# MCF5441x register map
Vendor: NXP; File version: 1.0
Registers are 32-bit, read-write, reset 0x0 unless marked. A register's access mark holds for its fields unless they carry their own. Offsets are from the block's base; [hi:lo] are bit positions; 'fields as' and 'values as' point back to an identical list.

## PIT0
Base 0xFC080000
Same registers: PIT1 0xFC084000, PIT2 0xFC088000, PIT3 0xFC08C000
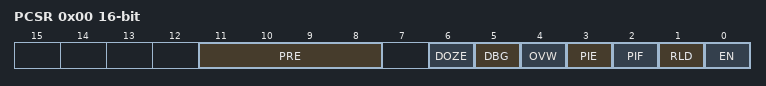
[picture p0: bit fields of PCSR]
0x00 PCSR 16-bit
  [11:8] PRE
  [6] DOZE
  [5] DBG
  [4] OVW
  [3] PIE
    0=DISABLED; 1=ENABLED
  [2] PIF write-1-clears
  [1] RLD
  [0] EN
    0=DISABLED; 1=ENABLED
0x02 PMR 16-bit reset 0xFFFF
  [15:0] PM
0x04 PCNTR 16-bit ro reset 0xFFFF

## SCM
Base 0xFC040000
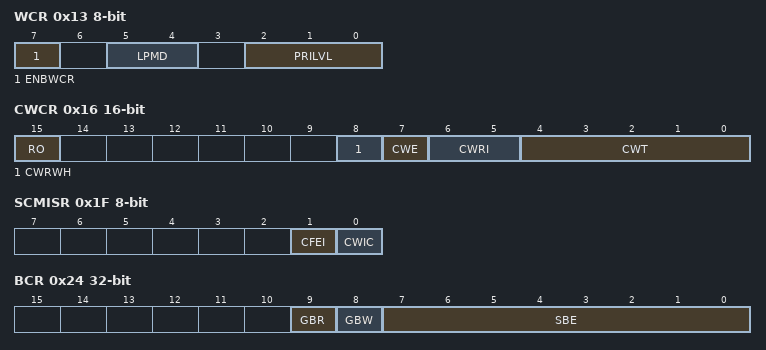
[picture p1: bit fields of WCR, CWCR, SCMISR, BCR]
0x13 WCR 8-bit
  [7] ENBWCR
  [5:4] LPMD
    0=RUN; 1=DOZE; 2=WAIT; 3=STOP
  [2:0] PRILVL
0x16 CWCR 16-bit
  [15] RO
  [8] CWRWH
  [7] CWE
    0=DISABLED; 1=ENABLED
  [6:5] CWRI
  [4:0] CWT
0x1B CWSR 8-bit reset not defined
0x1F SCMISR 8-bit
  [1] CFEI write-1-clears, [0] CWIC write-1-clears
0x24 BCR
  [9] GBR
    0=DISABLED; 1=ENABLED
  [8] GBW
    0=DISABLED; 1=ENABLED
  [7:0] SBE
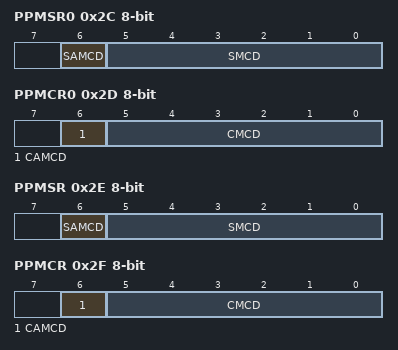
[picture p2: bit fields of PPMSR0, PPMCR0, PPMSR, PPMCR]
0x2C PPMSR0 8-bit wo
  [6] SAMCD, [5:0] SMCD
0x2D PPMCR0 8-bit wo
  [6] CAMCD, [5:0] CMCD
0x2E PPMSR 8-bit wo
  [6] SAMCD, [5:0] SMCD
0x2F PPMCR 8-bit wo
  [6] CAMCD, [5:0] CMCD
0x30 PPMHR0 reset 0x7E1EFBFF
0x34 PPMLR0 reset 0xFFDEF300
0x38 PPMHR reset 0xFFFFFFCF
0x3C PPMLR reset 0x3F00C0F4
0x70 CFADR ro reset not defined
  [31:0] ADDR
0x75 CFIER 8-bit
  [0] ECFEI
0x76 CFLOC 8-bit ro reset not defined
  [7] LOC
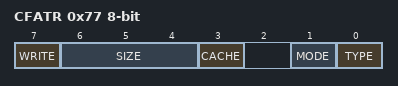
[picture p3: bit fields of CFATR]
0x77 CFATR 8-bit ro reset not defined
  [7] WRITE
    0=READ_ACCESS; 1=WRITE_ACCESS
  [6:4] SIZE
  [3] CACHE
    0=NON_CACHEABLE; 1=CACHEABLE
  [1] MODE
    0=USER_MODE; 1=SUPERVISOR_MODE
  [0] TYPE
    0=INSTRUCTION; 1=DATA
0x7C CFDTR ro reset not defined

## RGPIO
Base 0x8C000000
0x00 DIR 16-bit
0x02 DATA 16-bit
0x04 ENB 16-bit
0x06 CLR 16-bit wo reset not defined
0x0A SET 16-bit wo reset not defined
0x0E TOG 16-bit wo reset not defined

## RNG
Base 0xFC0C4000
0x00 RNGVER reset 0x10000280
0x04 RNGCMD
0x08 RNGCR
0x0C RNGSR ro reset 0x500D
0x10 RNGESR ro
0x14 RNGOUT ro
  [31:0] DATA read-modifies
0x18 RNGER wo

## RTC
Base 0xFC0A8000
0x00 YEARMON 16-bit reset 0x1
0x02 DAYS 16-bit reset 0x1
0x04 HOURMIN 16-bit
0x06 SECONDS 16-bit
0x08 ALM_YRMON 16-bit
0x0A ALM_DAYS 16-bit
0x0C ALM_HM 16-bit
0x0E ALM_SEC 16-bit
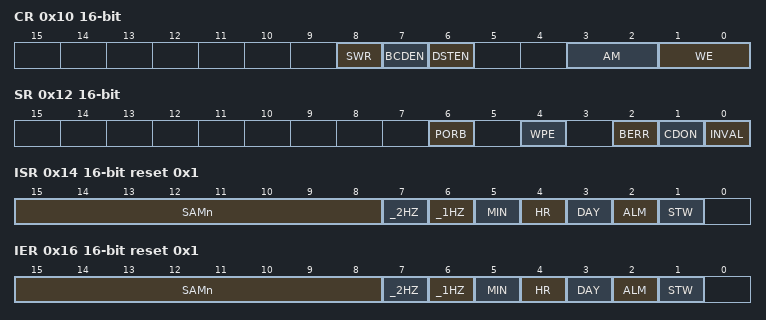
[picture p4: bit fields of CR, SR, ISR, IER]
0x10 CR 16-bit
  [8] SWR
  [7] BCDEN
  [6] DSTEN
    0=DISABLED; 1=ENABLED
  [3:2] AM
  [1:0] WE
0x12 SR 16-bit
  [6] PORB
  [4] WPE
    0=DISABLED; 1=ENABLED
  [2] BERR
  [1] CDON
  [0] INVAL
0x14 ISR 16-bit reset 0x1
  [15:8] SAMn write-1-clears, [7] _2HZ write-1-clears, [6] _1HZ write-1-clears, [5] MIN write-1-clears, [4] HR write-1-clears, [3] DAY write-1-clears, [2] ALM write-1-clears, [1] STW write-1-clears
0x16 IER 16-bit reset 0x1
  [15:8] SAMn
  [7] _2HZ
    0=DISABLE; 1=ENABLE
  [6] _1HZ
  [5] MIN
    0=DISABLE; 1=ENABLE
  [4] HR
    0=DISABLE; 1=ENABLE
  [3] DAY
    0=DISABLE; 1=ENABLE
  [2] ALM
    0=DISABLE; 1=ENABLE
  [1] STW
    0=DISABLE; 1=ENABLE
0x18 COUNT_DN 16-bit
  [7:0] COUNT
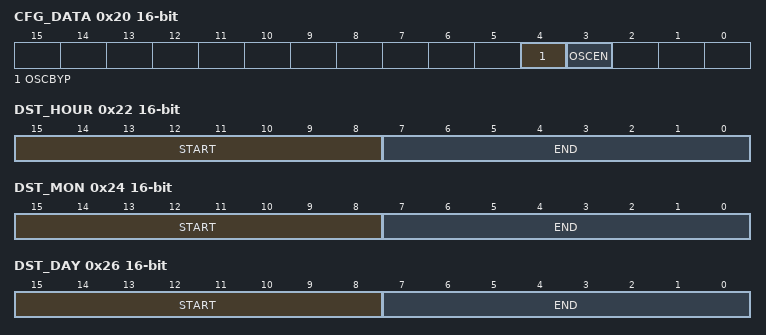
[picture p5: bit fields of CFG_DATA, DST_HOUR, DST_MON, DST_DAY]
0x20 CFG_DATA 16-bit
  [4] OSCBYP, [3] OSCEN
0x22 DST_HOUR 16-bit
  [15:8] START, [7:0] END
0x24 DST_MON 16-bit
  [15:8] START, [7:0] END
0x26 DST_DAY 16-bit
  [15:8] START, [7:0] END
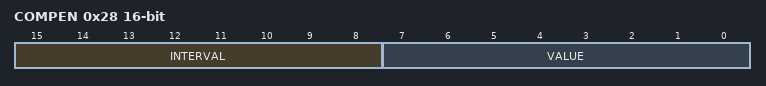
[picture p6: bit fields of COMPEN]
0x28 COMPEN 16-bit
  [15:8] INTERVAL, [7:0] VALUE
0x32 UP_CNTRH 16-bit ro
0x34 UP_CNTRL 16-bit ro

## SIM
Base 0xFC0AC000
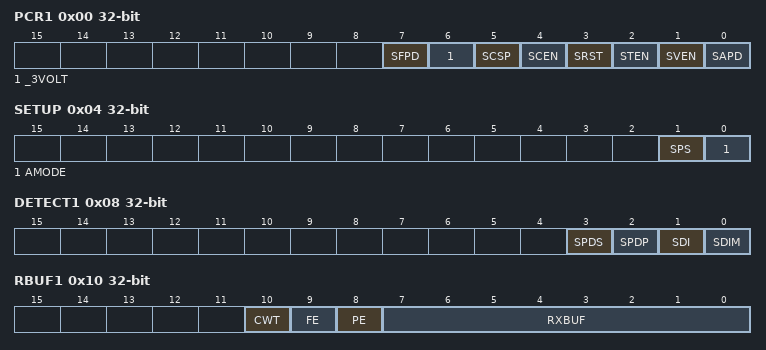
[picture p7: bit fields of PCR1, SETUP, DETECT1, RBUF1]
0x00 PCR1
  [7] SFPD
    0=NO_EFFECT; 1=START_AUTO_POWER_DOWN
  [6] _3VOLT
  [5] SCSP
  [4] SCEN
    0=DISABLED; 1=ENABLED
  [3] SRST
    0=INACTIVE; 1=ACTIVE
  [2] STEN
  [1] SVEN
    0=DISABLED; 1=ENABLED
  [0] SAPD
    0=DISABLED; 1=ENABLED
0x04 SETUP
  [1] SPS
    0=PORT_0_ENABLED; 1=PORT_1_ENABLED
  [0] AMODE
    0=DISABLED; 1=ENABLED
0x08 DETECT1 reset not defined
  [3] SPDS
  [2] SPDP
    0=LOW; 1=HIGH
  [1] SDI write-1-clears
  [0] SDIM
    0=ENABLED; 1=MASKED
0x0C TBUF1
0x10 RBUF1 ro
  [10] CWT
    0=ON_TIME; 1=LATE
  [9] FE
  [8] PE
  [7:0] RXBUF read-modifies
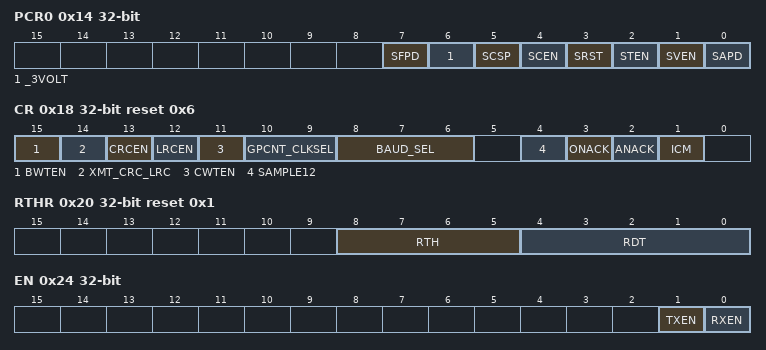
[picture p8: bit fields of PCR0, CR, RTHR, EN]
0x14 PCR0
  fields as PCR1
0x18 CR reset 0x6
  [15] BWTEN
    0=DISABLE_BWT_AND_BGT; 1=ENABLE_BWT_AND_BGT
  [14] XMT_CRC_LRC
  [13] CRCEN
  [12] LRCEN
  [11] CWTEN
  [10:9] GPCNT_CLKSEL
    0=DISABLED_RESET; 1=CARD_CLOCK; 2=RECEIVE_CLOCK; 3=ETU_CLOCK_TRANSMIT_CLOCK
  [8:6] BAUD_SEL
  [4] SAMPLE12
    0=DIVIDE_BY_8; 1=DIVIDE_BY_12
  [3] ONACK
  [2] ANACK
  [1] ICM
0x1C PRE reset 0x2
  [7:0] PRESCALER
0x20 RTHR reset 0x1
  [8:5] RTH, [4:0] RDT
0x24 EN
  [1] TXEN
    0=DISABLED; 1=ENABLED
  [0] RXEN
    0=DISABLED; 1=ENABLED
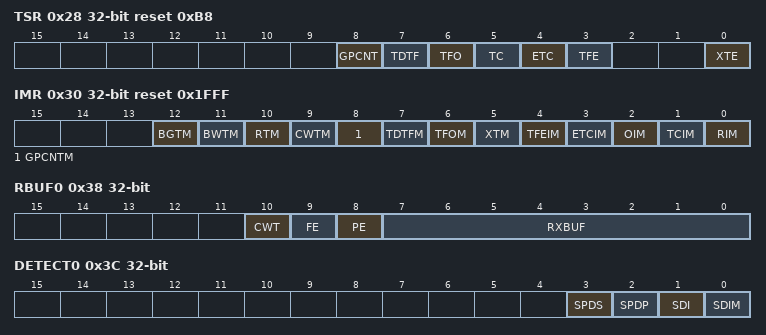
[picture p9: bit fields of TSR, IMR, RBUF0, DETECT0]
0x28 TSR reset 0xB8
  [8] GPCNT write-1-clears, [7] TDTF write-1-clears, [6] TFO, [5] TC write-1-clears, [4] ETC write-1-clears, [3] TFE write-1-clears, [0] XTE write-1-clears
0x2C RSR reset 0x40
0x30 IMR reset 0x1FFF
  [all] fields
    0=ENABLED; 1=MASKED
  [12] BGTM
  [11] BWTM
  [10] RTM
  [9] CWTM
  [8] GPCNTM
  [7] TDTFM
  [6] TFOM
  [5] XTM
  [4] TFEIM
  [3] ETCIM
  [2] OIM
  [1] TCIM
  [0] RIM
0x34 TBUF0
0x38 RBUF0 ro
  fields as RBUF1
0x3C DETECT0 reset not defined
  fields as DETECT1
0x40 FORMAT0
  [0] IC
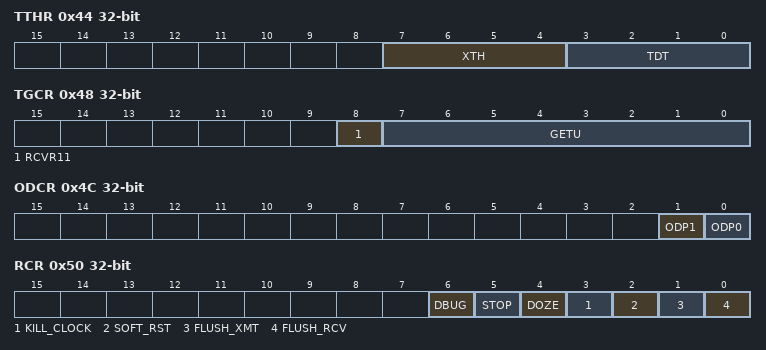
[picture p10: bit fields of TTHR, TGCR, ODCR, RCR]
0x44 TTHR
  [7:4] XTH, [3:0] TDT
0x48 TGCR
  [8] RCVR11, [7:0] GETU
0x4C ODCR
  [1] ODP1
    1=SIM_DATA1_IS_OPEN_DRAIN
  [0] ODP0
    1=SIM_DATA0_IS_OPEN_DRAIN
0x50 RCR
  [6] DBUG
  [5] STOP
  [4] DOZE
  [3] KILL_CLOCK
    0=ENABLED; 1=DISABLED
  [2] SOFT_RST
    0=NORMAL_OPERATION; 1=HELD_IN_RESET
  [1] FLUSH_XMT
  [0] FLUSH_RCV
0x54 CWTR reset 0xFFFF
  [15:0] CWT
0x58 GPCNT reset 0xFFFF
  [15:0] GPCNT
0x5C DIV reset 0xFF
  [7:0] DIVISOR
0x60 BWT reset 0xFFFF
  [15:0] BWT
0x64 BGT
  [15:0] BGT
0x68 BWTH reset 0xFFFF
  [15:0] BWT
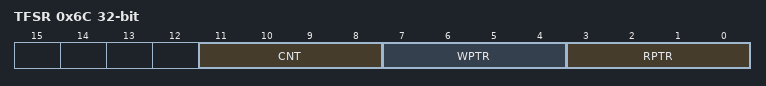
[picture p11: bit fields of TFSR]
0x6C TFSR ro
  [11:8] CNT
    0=FIFO_IS_EMPTY_OR_FULL; 1=ONE_BYTE_IN_THE_FIFO
  [7:4] WPTR
  [3:0] RPTR
0x70 RFCR ro
  [8:0] CNT
0x74 RFWP ro
  [8:0] WPTR
0x78 RFRP ro
  [8:0] RPTR
